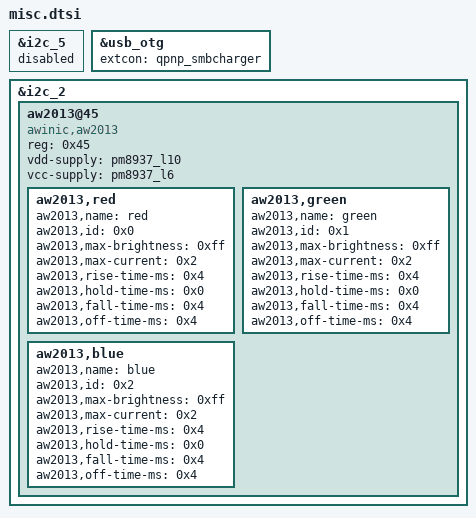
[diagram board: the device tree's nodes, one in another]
&i2c_5 {
	status = "disabled";
};

&usb_otg {
	extcon = <&qpnp_smbcharger>;
};

&i2c_2 {
	status = "ok";
	aw2013@45 {
		compatible = "awinic,aw2013";
		reg = <0x45>;
		vdd-supply = <&pm8937_l10>;
		vcc-supply = <&pm8937_l6>;

		aw2013,red {
			aw2013,name = "red";
			aw2013,id = <0x0>;
			aw2013,max-brightness = <0xff>;
			aw2013,max-current = <0x2>;
			aw2013,rise-time-ms = <0x4>;
			aw2013,hold-time-ms = <0x0>;
			aw2013,fall-time-ms = <0x4>;
			aw2013,off-time-ms = <0x4>;
		};

		aw2013,green {
			aw2013,name = "green";
			aw2013,id = <0x1>;
			aw2013,max-brightness = <0xff>;
			aw2013,max-current = <0x2>;
			aw2013,rise-time-ms = <0x4>;
			aw2013,hold-time-ms = <0x0>;
			aw2013,fall-time-ms = <0x4>;
			aw2013,off-time-ms = <0x4>;
		};

		aw2013,blue {
			aw2013,name = "blue";
			aw2013,id = <0x2>;
			aw2013,max-brightness = <0xff>;
			aw2013,max-current = <0x2>;
			aw2013,rise-time-ms = <0x4>;
			aw2013,hold-time-ms = <0x0>;
			aw2013,fall-time-ms = <0x4>;
			aw2013,off-time-ms = <0x4>;
		};
	};
};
